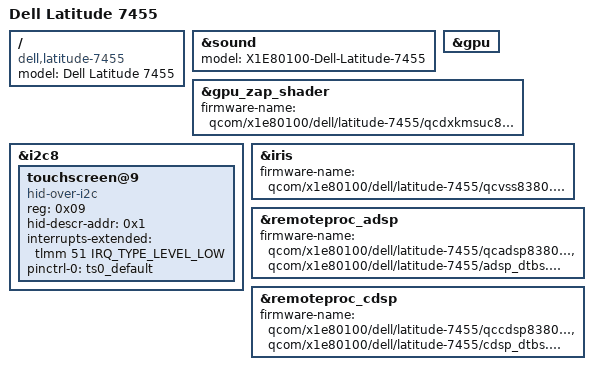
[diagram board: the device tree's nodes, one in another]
// SPDX-License-Identifier: BSD-3-Clause
/*
 * Copyright (c) 2025 Val Packett <val@packett.cool>
 */
/dts-v1/;

#include "x1e80100.dtsi"
#include "x1-dell-thena.dtsi"

/ {
	model = "Dell Latitude 7455";
	compatible = "dell,latitude-7455", "qcom,x1e80100";
};

&sound {
	model = "X1E80100-Dell-Latitude-7455";
};

&gpu {
	status = "okay";
};

&gpu_zap_shader {
	firmware-name = "qcom/x1e80100/dell/latitude-7455/qcdxkmsuc8380.mbn";
};

&i2c8 {
	/* LXST2021 */
	touchscreen@9 {
		compatible = "hid-over-i2c";
		reg = <0x09>;

		hid-descr-addr = <0x1>;
		interrupts-extended = <&tlmm 51 IRQ_TYPE_LEVEL_LOW>;

		pinctrl-0 = <&ts0_default>;
		pinctrl-names = "default";
	};
};

&iris {
	firmware-name = "qcom/x1e80100/dell/latitude-7455/qcvss8380.mbn";
	status = "okay";
};

&remoteproc_adsp {
	firmware-name = "qcom/x1e80100/dell/latitude-7455/qcadsp8380.mbn",
			"qcom/x1e80100/dell/latitude-7455/adsp_dtbs.elf";

	status = "okay";
};

&remoteproc_cdsp {
	firmware-name = "qcom/x1e80100/dell/latitude-7455/qccdsp8380.mbn",
			"qcom/x1e80100/dell/latitude-7455/cdsp_dtbs.elf";

	status = "okay";
};
